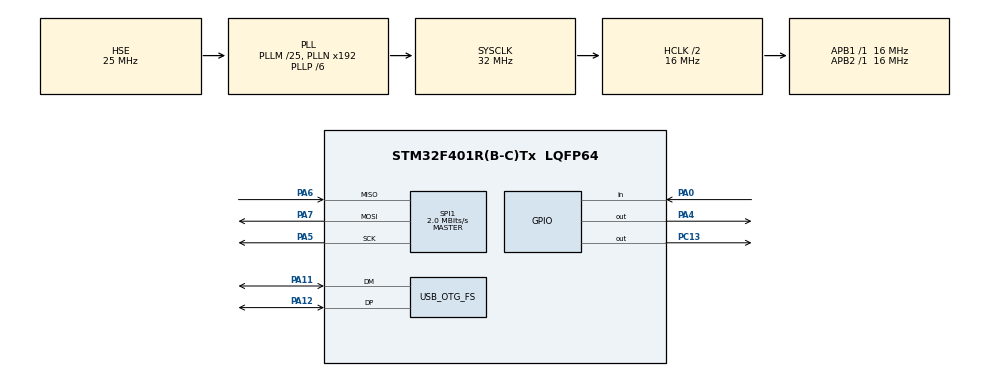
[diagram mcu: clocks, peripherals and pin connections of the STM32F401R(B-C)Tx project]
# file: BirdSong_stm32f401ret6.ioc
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Mcu.Family=STM32F4
PC15-OSC32_OUT.Mode=LSE-External-Oscillator
PA6.Mode=Full_Duplex_Master
USB_DEVICE.CLASS_NAME_FS=MSC
RCC.CortexFreq_Value=16000000
PA7.Mode=Full_Duplex_Master
SPI1.VirtualType=VM_MASTER
USB_DEVICE.VirtualModeFS=Msc_FS
PH1\ -\ OSC_OUT.Mode=HSE-External-Oscillator
PA11.Mode=Device_Only
PC14-OSC32_IN.Signal=RCC_OSC32_IN
PC13-ANTI_TAMP.PinState=GPIO_PIN_SET
RCC.SYSCLKSource=RCC_SYSCLKSOURCE_PLLCLK
ProjectManager.StackSize=0x400
PA0-WKUP.Signal=GPIO_Input
PH0\ -\ OSC_IN.Mode=HSE-External-Oscillator
PA12.Signal=USB_OTG_FS_DP
PH0\ -\ OSC_IN.Signal=RCC_OSC_IN
ProjectManager.TargetToolchain=STM32CubeIDE
SPI1.Direction=SPI_DIRECTION_2LINES
RCC.HCLKFreq_Value=16000000
RCC.APB2TimFreq_Value=16000000
SPI1.CalculateBaudRate=2.0 MBits/s
PC15-OSC32_OUT.Signal=RCC_OSC32_OUT
RCC.AHBFreq_Value=16000000
PA5.Signal=SPI1_SCK
RCC.HSE_VALUE=25000000
PH1\ -\ OSC_OUT.Signal=RCC_OSC_OUT
board=custom
PC13-ANTI_TAMP.Signal=GPIO_Output
RCC.VCOOutputFreq_Value=192000000
PA4.GPIO_Speed=GPIO_SPEED_FREQ_HIGH
RCC.APB2Freq_Value=16000000
PC14-OSC32_IN.Mode=LSE-External-Oscillator
SPI1.Mode=SPI_MODE_MASTER
RCC.AHBCLKDivider=RCC_SYSCLK_DIV2
Mcu.Name=STM32F401R(B-C)Tx
RCC.48MHZClocksFreq_Value=48000000
PA4.Signal=GPIO_Output
RCC.SYSCLKFreq_VALUE=32000000
Mcu.Package=LQFP64
PA6.Signal=SPI1_MISO
PA12.Mode=Device_Only
NVIC.OTG_FS_IRQn=true\:0\:0\:false\:false\:true\:false\:true
PA11.Signal=USB_OTG_FS_DM
USB_OTG_FS.VirtualMode=Device_Only
ProjectManager.HeapSize=0x200
RCC.HSI_VALUE=16000000
RCC.PLLP=RCC_PLLP_DIV6
NVIC.PriorityGroup=NVIC_PRIORITYGROUP_4
RCC.PLLM=25
RCC.APB1TimFreq_Value=16000000
VP_USB_DEVICE_VS_USB_DEVICE_MSC_FS.Mode=MSC_FS
RCC.APB1Freq_Value=16000000
SPI1.BaudRatePrescaler=SPI_BAUDRATEPRESCALER_8
USB_DEVICE.VirtualMode=Msc
PA5.Mode=Full_Duplex_Master
PA7.Signal=SPI1_MOSI

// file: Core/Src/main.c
/* USER CODE BEGIN Header */
/**
  ******************************************************************************
  * @file           : main.c
  * @brief          : Main program body
  ******************************************************************************
  * @attention
  *
  * <h2><center>&copy; Copyright (c) 2026 STMicroelectronics.
  * All rights reserved.</center></h2>
  *
  * This software component is licensed by ST under Ultimate Liberty license
  * SLA0044, the "License"; You may not use this file except in compliance with
  * the License. You may obtain a copy of the License at:
  *                             www.st.com/SLA0044
  *
  ******************************************************************************
  */
/* USER CODE END Header */
#include "main.h"
#include "usb_device.h"

SPI_HandleTypeDef hspi1;

void SystemClock_Config(void);
static void MX_GPIO_Init(void);
static void MX_SPI1_Init(void);

int main(void)
{

  /* MCU Configuration--------------------------------------------------------*/

  /* Reset of all peripherals, Initializes the Flash interface and the Systick. */
  HAL_Init();

  /* Configure the system clock */
  SystemClock_Config();

  /* Initialize all configured peripherals */
  MX_GPIO_Init();
  MX_USB_DEVICE_Init();
  MX_SPI1_Init();

  /* Infinite loop */
  /* USER CODE BEGIN WHILE */
  //Initialization is True
  HAL_Delay(1000);
  LED_PORT->BSRR |= (1<<(LED_PIN+16));
  HAL_Delay(1000);
  LED_PORT->BSRR |= (1<<LED_PIN);
  HAL_Delay(1000);
  LED_PORT->BSRR |= (1<<(LED_PIN+16));
  HAL_Delay(1000);
  LED_PORT->BSRR |= (1<<LED_PIN);
  while (1)
  {
    /* USER CODE END WHILE */

  }
}

void SystemClock_Config(void)
{
  RCC_OscInitTypeDef RCC_OscInitStruct = {0};
  RCC_ClkInitTypeDef RCC_ClkInitStruct = {0};

  /** Configure the main internal regulator output voltage
  */
  __HAL_RCC_PWR_CLK_ENABLE();
  __HAL_PWR_VOLTAGESCALING_CONFIG(PWR_REGULATOR_VOLTAGE_SCALE2);
  /** Initializes the RCC Oscillators according to the specified parameters
  * in the RCC_OscInitTypeDef structure.
  */
  RCC_OscInitStruct.OscillatorType = RCC_OSCILLATORTYPE_HSE;
  RCC_OscInitStruct.HSEState = RCC_HSE_ON;
  RCC_OscInitStruct.PLL.PLLState = RCC_PLL_ON;
  RCC_OscInitStruct.PLL.PLLSource = RCC_PLLSOURCE_HSE;
  RCC_OscInitStruct.PLL.PLLM = 25;
  RCC_OscInitStruct.PLL.PLLN = 192;
  RCC_OscInitStruct.PLL.PLLP = RCC_PLLP_DIV6;
  RCC_OscInitStruct.PLL.PLLQ = 4;
  if (HAL_RCC_OscConfig(&RCC_OscInitStruct) != HAL_OK)
  {
    Error_Handler();
  }
  /** Initializes the CPU, AHB and APB buses clocks
  */
  RCC_ClkInitStruct.ClockType = RCC_CLOCKTYPE_HCLK|RCC_CLOCKTYPE_SYSCLK
                              |RCC_CLOCKTYPE_PCLK1|RCC_CLOCKTYPE_PCLK2;
  RCC_ClkInitStruct.SYSCLKSource = RCC_SYSCLKSOURCE_PLLCLK;
  RCC_ClkInitStruct.AHBCLKDivider = RCC_SYSCLK_DIV2;
  RCC_ClkInitStruct.APB1CLKDivider = RCC_HCLK_DIV1;
  RCC_ClkInitStruct.APB2CLKDivider = RCC_HCLK_DIV1;

  if (HAL_RCC_ClockConfig(&RCC_ClkInitStruct, FLASH_LATENCY_0) != HAL_OK)
  {
    Error_Handler();
  }
}

static void MX_SPI1_Init(void)
{

  /* SPI1 parameter configuration*/
  hspi1.Instance = SPI1;
  hspi1.Init.Mode = SPI_MODE_MASTER;
  hspi1.Init.Direction = SPI_DIRECTION_2LINES;
  hspi1.Init.DataSize = SPI_DATASIZE_8BIT;
  hspi1.Init.CLKPolarity = SPI_POLARITY_LOW;
  hspi1.Init.CLKPhase = SPI_PHASE_1EDGE;
  hspi1.Init.NSS = SPI_NSS_SOFT;
  hspi1.Init.BaudRatePrescaler = SPI_BAUDRATEPRESCALER_8;
  hspi1.Init.FirstBit = SPI_FIRSTBIT_MSB;
  hspi1.Init.TIMode = SPI_TIMODE_DISABLE;
  hspi1.Init.CRCCalculation = SPI_CRCCALCULATION_DISABLE;
  hspi1.Init.CRCPolynomial = 10;
  if (HAL_SPI_Init(&hspi1) != HAL_OK)
  {
    Error_Handler();
  }

}

static void MX_GPIO_Init(void)
{
  GPIO_InitTypeDef GPIO_InitStruct = {0};

  /* GPIO Ports Clock Enable */
  __HAL_RCC_GPIOC_CLK_ENABLE();
  __HAL_RCC_GPIOH_CLK_ENABLE();
  __HAL_RCC_GPIOA_CLK_ENABLE();

  /*Configure GPIO pin Output Level */
  HAL_GPIO_WritePin(GPIOC, GPIO_PIN_13, GPIO_PIN_SET);

  /*Configure GPIO pin Output Level */
  HAL_GPIO_WritePin(GPIOA, GPIO_PIN_4, GPIO_PIN_RESET);

  /*Configure GPIO pin : PC13 */
  GPIO_InitStruct.Pin = GPIO_PIN_13;
  GPIO_InitStruct.Mode = GPIO_MODE_OUTPUT_PP;
  GPIO_InitStruct.Pull = GPIO_NOPULL;
  GPIO_InitStruct.Speed = GPIO_SPEED_FREQ_LOW;
  HAL_GPIO_Init(GPIOC, &GPIO_InitStruct);

  /*Configure GPIO pin : PA0 */
  GPIO_InitStruct.Pin = GPIO_PIN_0;
  GPIO_InitStruct.Mode = GPIO_MODE_INPUT;
  GPIO_InitStruct.Pull = GPIO_NOPULL;
  HAL_GPIO_Init(GPIOA, &GPIO_InitStruct);

  /*Configure GPIO pin : PA4 */
  GPIO_InitStruct.Pin = GPIO_PIN_4;
  GPIO_InitStruct.Mode = GPIO_MODE_OUTPUT_PP;
  GPIO_InitStruct.Pull = GPIO_NOPULL;
  GPIO_InitStruct.Speed = GPIO_SPEED_FREQ_HIGH;
  HAL_GPIO_Init(GPIOA, &GPIO_InitStruct);

}

void Error_Handler(void)
{
  __disable_irq();
  while (1)
  {
  }
}

/************************ (C) COPYRIGHT STMicroelectronics *****END OF FILE****/
